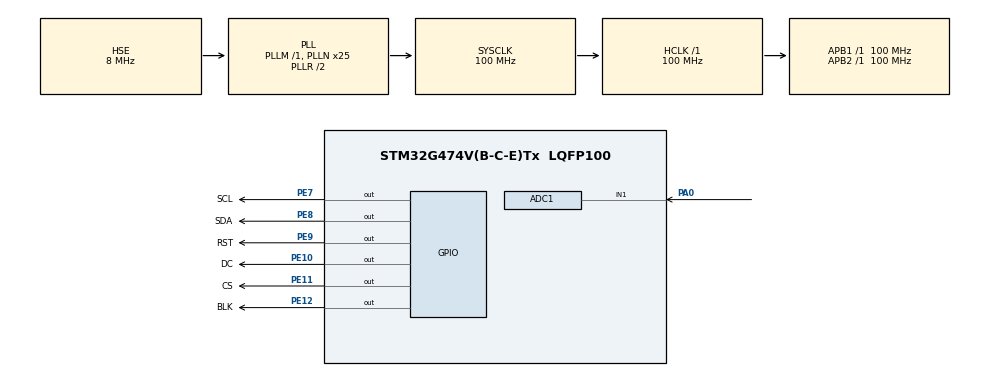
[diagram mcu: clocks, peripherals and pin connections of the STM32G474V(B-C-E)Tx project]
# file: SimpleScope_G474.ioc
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ADC1.Channel-3\#ChannelRegularConversion=ADC_CHANNEL_1
ADC1.NbrOfConversionFlag=1
ADC1.OffsetNumber-3\#ChannelRegularConversion=ADC_OFFSET_NONE
ADC1.Rank-3\#ChannelRegularConversion=1
ADC1.SamplingTime-3\#ChannelRegularConversion=ADC_SAMPLETIME_247CYCLES_5
ADC1.master=1
Mcu.Family=STM32G4
Mcu.Name=STM32G474V(B-C-E)Tx
Mcu.Package=LQFP100
NVIC.ADC1_2_IRQn=true\:0\:0\:false\:false\:true\:true\:true\:true
NVIC.PriorityGroup=NVIC_PRIORITYGROUP_4
PA0.Mode=IN1-Single-Ended
PA0.Signal=ADC1_IN1
PA13.Mode=Serial_Wire
PA13.Signal=SYS_JTMS-SWDIO
PA14.Mode=Serial_Wire
PA14.Signal=SYS_JTCK-SWCLK
PE10.GPIO_Label=DC
PE10.GPIO_Speed=GPIO_SPEED_FREQ_VERY_HIGH
PE10.Signal=GPIO_Output
PE11.GPIO_Label=CS
PE11.GPIO_Speed=GPIO_SPEED_FREQ_VERY_HIGH
PE11.Signal=GPIO_Output
PE12.GPIO_Label=BLK
PE12.GPIO_Speed=GPIO_SPEED_FREQ_VERY_HIGH
PE12.PinState=GPIO_PIN_RESET
PE12.Signal=GPIO_Output
PE7.GPIO_Label=SCL
PE7.GPIO_Speed=GPIO_SPEED_FREQ_VERY_HIGH
PE7.Signal=GPIO_Output
PE8.GPIO_Label=SDA
PE8.GPIO_Speed=GPIO_SPEED_FREQ_VERY_HIGH
PE8.Signal=GPIO_Output
PE9.GPIO_Label=RST
PE9.GPIO_Speed=GPIO_SPEED_FREQ_VERY_HIGH
PE9.Signal=GPIO_Output
PF0-OSC_IN.Mode=HSE-External-Oscillator
PF0-OSC_IN.Signal=RCC_OSC_IN
PF1-OSC_OUT.Mode=HSE-External-Oscillator
PF1-OSC_OUT.Signal=RCC_OSC_OUT
ProjectManager.HeapSize=0x200
ProjectManager.StackSize=0x400
ProjectManager.TargetToolchain=MDK-ARM V5.32
RCC.ADC12Freq_Value=100000000
RCC.ADC345Freq_Value=100000000
RCC.AHBFreq_Value=100000000
RCC.APB1Freq_Value=100000000
RCC.APB1TimFreq_Value=100000000
RCC.APB2Freq_Value=100000000
RCC.APB2TimFreq_Value=100000000
RCC.CortexFreq_Value=100000000
RCC.EXTERNAL_CLOCK_VALUE=12288000
RCC.HCLKFreq_Value=100000000
RCC.HSE_VALUE=8000000
RCC.HSI48_VALUE=48000000
RCC.HSI_VALUE=16000000
RCC.LSE_VALUE=32768
RCC.PLLN=25
RCC.PLLSourceVirtual=RCC_PLLSOURCE_HSE
RCC.SYSCLKFreq_VALUE=100000000
RCC.SYSCLKSource=RCC_SYSCLKSOURCE_PLLCLK
RCC.USBFreq_Value=100000000
RCC.VCOOutputFreq_Value=200000000
VP_SYS_VS_DBSignals.Mode=DisableDeadBatterySignals
VP_SYS_V_VREFBUF.Mode=ExternalMode
board=custom

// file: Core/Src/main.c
/* USER CODE BEGIN Header */
/**
  ******************************************************************************
  * @file           : main.c
  * @brief          : Main program body
  ******************************************************************************
  * @attention
  *
  * Copyright (c) 2026 STMicroelectronics.
  * All rights reserved.
  *
  * This software is licensed under terms that can be found in the LICENSE file
  * in the root directory of this software component.
  * If no LICENSE file comes with this software, it is provided AS-IS.
  *
  ******************************************************************************
  */
/* USER CODE END Header */
#include "main.h"
#include "adc.h"
#include "gpio.h"

/* USER CODE BEGIN Includes */
#include "app_oscilloscope.h"

/* USER CODE END Includes */

void SystemClock_Config(void);

int main(void)
{

  /* MCU Configuration--------------------------------------------------------*/

  /* Reset of all peripherals, Initializes the Flash interface and the Systick. */
  HAL_Init();

  /* Configure the system clock */
  SystemClock_Config();

  /* Initialize all configured peripherals */
  MX_GPIO_Init();
  MX_ADC1_Init();
  /* USER CODE BEGIN 2 */
  App_OscilloscopeInit();

  /* USER CODE END 2 */

  /* Infinite loop */
  while (1)
  {

    /* USER CODE BEGIN 3 */
    App_OscilloscopeFrame(&hadc1);
  }
  /* USER CODE END 3 */
}

void SystemClock_Config(void)
{
  RCC_OscInitTypeDef RCC_OscInitStruct = {0};
  RCC_ClkInitTypeDef RCC_ClkInitStruct = {0};

  /** Configure the main internal regulator output voltage
  */
  HAL_PWREx_ControlVoltageScaling(PWR_REGULATOR_VOLTAGE_SCALE1);

  /** Initializes the RCC Oscillators according to the specified parameters
  * in the RCC_OscInitTypeDef structure.
  */
  RCC_OscInitStruct.OscillatorType = RCC_OSCILLATORTYPE_HSE;
  RCC_OscInitStruct.HSEState = RCC_HSE_ON;
  RCC_OscInitStruct.PLL.PLLState = RCC_PLL_ON;
  RCC_OscInitStruct.PLL.PLLSource = RCC_PLLSOURCE_HSE;
  RCC_OscInitStruct.PLL.PLLM = RCC_PLLM_DIV1;
  RCC_OscInitStruct.PLL.PLLN = 25;
  RCC_OscInitStruct.PLL.PLLP = RCC_PLLP_DIV2;
  RCC_OscInitStruct.PLL.PLLQ = RCC_PLLQ_DIV2;
  RCC_OscInitStruct.PLL.PLLR = RCC_PLLR_DIV2;
  if (HAL_RCC_OscConfig(&RCC_OscInitStruct) != HAL_OK)
  {
    Error_Handler();
  }

  /** Initializes the CPU, AHB and APB buses clocks
  */
  RCC_ClkInitStruct.ClockType = RCC_CLOCKTYPE_HCLK|RCC_CLOCKTYPE_SYSCLK
                              |RCC_CLOCKTYPE_PCLK1|RCC_CLOCKTYPE_PCLK2;
  RCC_ClkInitStruct.SYSCLKSource = RCC_SYSCLKSOURCE_PLLCLK;
  RCC_ClkInitStruct.AHBCLKDivider = RCC_SYSCLK_DIV1;
  RCC_ClkInitStruct.APB1CLKDivider = RCC_HCLK_DIV1;
  RCC_ClkInitStruct.APB2CLKDivider = RCC_HCLK_DIV1;

  if (HAL_RCC_ClockConfig(&RCC_ClkInitStruct, FLASH_LATENCY_3) != HAL_OK)
  {
    Error_Handler();
  }
}

void Error_Handler(void)
{
  __disable_irq();
  while (1)
  {
  }
}
